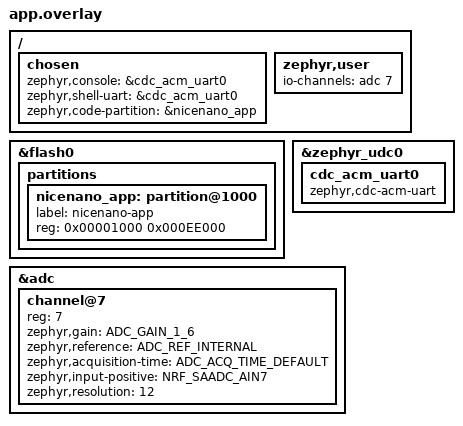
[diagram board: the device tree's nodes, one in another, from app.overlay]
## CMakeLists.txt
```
cmake_minimum_required(VERSION 3.20.0)
find_package(Zephyr REQUIRED HINTS $ENV{ZEPHYR_BASE})
project(nrf52840_nicenano_saadc)
target_sources(app PRIVATE src/main.c ../nrf52840_nicenano_common/ael_usb.c)
```

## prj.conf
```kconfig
CONFIG_GPIO=y
CONFIG_ADC=y
CONFIG_SERIAL=y
CONFIG_CONSOLE=y
CONFIG_UART_CONSOLE=y
CONFIG_STDOUT_CONSOLE=y
CONFIG_PRINTK=y
CONFIG_USB_DEVICE_STACK_NEXT=y
CONFIG_USBD_CDC_ACM_CLASS=y
CONFIG_CDC_ACM_SERIAL_INITIALIZE_AT_BOOT=y
CONFIG_CDC_ACM_SERIAL_PID=0x0011
CONFIG_CDC_ACM_SERIAL_PRODUCT_STRING="AEL nRF52840 SAADC"
CONFIG_BUILD_OUTPUT_UF2=y
CONFIG_BUILD_OUTPUT_UF2_FAMILY_ID="0x239A00B3"
CONFIG_FLASH_LOAD_OFFSET=0x1000
CONFIG_FLASH_LOAD_SIZE=0xEE000
```

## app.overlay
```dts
/*
 * SAADC: AIN7 = P0.31 (VBATT voltage divider, on-board)
 * No external wiring needed.
 * Console: USB CDC
 */

/ {
    chosen {
        zephyr,console = &cdc_acm_uart0;
        zephyr,shell-uart = &cdc_acm_uart0;
        zephyr,code-partition = &nicenano_app;
    };

    zephyr,user {
        /* VBATT divider on P0.31 = AIN7 */
        io-channels = <&adc 7>;
    };
};

&flash0 {
    partitions {
        nicenano_app: partition@1000 {
            label = "nicenano-app";
            reg = <0x00001000 0x000EE000>;
        };
    };
};

&zephyr_udc0 {
    cdc_acm_uart0: cdc_acm_uart0 {
        compatible = "zephyr,cdc-acm-uart";
    };
};

&adc {
    status = "okay";
    #address-cells = <1>;
    #size-cells = <0>;

    channel@7 {
        reg = <7>;
        zephyr,gain = "ADC_GAIN_1_6";
        zephyr,reference = "ADC_REF_INTERNAL";
        zephyr,acquisition-time = <ADC_ACQ_TIME_DEFAULT>;
        zephyr,input-positive = <NRF_SAADC_AIN7>;
        zephyr,resolution = <12>;
    };
};
```

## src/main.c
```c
/*
 * AEL Stage 2 — nRF52840 nice!nano SAADC test
 *
 * Wiring: none — reads P0.31 (AIN7), the on-board VBATT voltage divider.
 * When powered from USB (5 V), VBATT divider reads ~VCC/2 ≈ 1.65 V.
 *
 * SAADC config: AIN7, gain=1/6, ref=600 mV internal, 12-bit.
 * At VCC=3.3 V, P0.31 ≈ VCC/2 ≈ 1.65 V.
 * Raw ADC = (1.65 / (0.6 × 6)) × 4095 ≈ 1879 counts.
 * Acceptance window: 100–4000 (sanity check: non-zero, not railed).
 *
 * Reports: [SAADC] raw=%d mv_approx=%d PASS|FAIL
 *          AEL_SAADC_PASS|FAIL
 */

#include <zephyr/kernel.h>
#include <zephyr/sys/printk.h>
#include <zephyr/drivers/adc.h>

#define ADC_NODE    DT_NODELABEL(adc)
#define ADC_CH      7

static const struct adc_dt_spec adc_ch7 =
    ADC_DT_SPEC_GET_BY_IDX(DT_PATH(zephyr_user), 0);

int main(void)
{
    k_msleep(1500);
    printk("AEL_SAADC_START\n");

    if (!adc_is_ready_dt(&adc_ch7)) {
        printk("[SAADC] device_not_ready FAIL\n");
        printk("AEL_SAADC_FAIL\n");
        return -1;
    }

    int ret = adc_channel_setup_dt(&adc_ch7);
    if (ret != 0) {
        printk("[SAADC] channel_setup_err=%d FAIL\n", ret);
        printk("AEL_SAADC_FAIL\n");
        return -1;
    }

    /* Take 4 samples and average */
    int32_t total = 0;
    int samples   = 4;
    for (int s = 0; s < samples; s++) {
        int16_t raw = 0;
        struct adc_sequence seq = {
            .channels    = BIT(adc_ch7.channel_id),
            .buffer      = &raw,
            .buffer_size = sizeof(raw),
            .resolution  = 12,
        };
        ret = adc_read_dt(&adc_ch7, &seq);
        if (ret != 0) {
            printk("[SAADC] read_err=%d FAIL\n", ret);
            printk("AEL_SAADC_FAIL\n");
            return -1;
        }
        total += raw;
        k_msleep(10);
    }
    int32_t raw_avg = total / samples;

    /* Convert to mV: Vref=600 mV, gain=1/6 → full-scale = 600×6 = 3600 mV */
    int32_t mv_approx = (int32_t)((int64_t)raw_avg * 3600 / 4095);

    bool pass = (raw_avg >= 100 && raw_avg <= 4000);
    printk("[SAADC] raw=%d mv_approx=%d %s\n", raw_avg, mv_approx, pass ? "PASS" : "FAIL");

    while (1) {
        printk("AEL_SAADC_%s\n", pass ? "PASS" : "FAIL");
        k_msleep(3000);
    }
    return 0;
}
```
